# STM32MP157 register map
File version: 1.6
CPU: CM4 r0p1, little endian, no MPU, FPU, 4 interrupt priority bits
Registers are 32-bit, read-write, reset 0x0 unless marked. A register's access mark holds for its fields unless they carry their own. Offsets are from the block's base; [hi:lo] are bit positions; {n}, {i} and the like mark numbered series.

## ETZPC
Base 0x5C007000
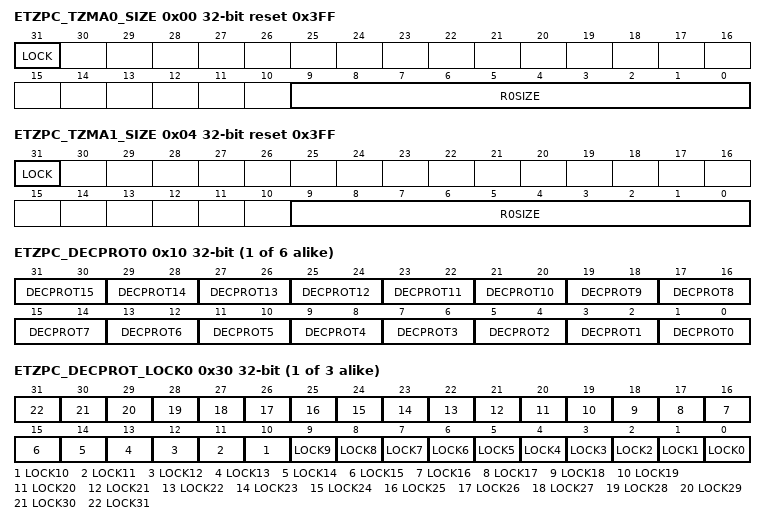
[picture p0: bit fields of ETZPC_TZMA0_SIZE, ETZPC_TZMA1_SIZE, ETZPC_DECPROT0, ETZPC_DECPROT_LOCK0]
0x00 ETZPC_TZMA0_SIZE reset 0x3FF — ETZPC ROM secure size definition
  [31] LOCK, [9:0] R0SIZE
0x04 ETZPC_TZMA1_SIZE reset 0x3FF — ETZPC RAM secure size definition
  [31] LOCK, [9:0] R0SIZE
{0x10+4i} ETZPC_DECPROT{i} (i=0..5) — Register reset values
  [2n+1:2n] DECPROT{n} (n=0..15)
{0x30+4i} ETZPC_DECPROT_LOCK{i} (i=0..2)
  [n] LOCK{n} (n=0..31)
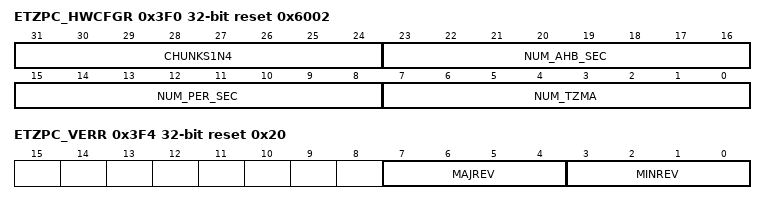
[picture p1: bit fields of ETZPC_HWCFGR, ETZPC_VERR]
0x3F0 ETZPC_HWCFGR ro reset 0x6002 — ETZPC IP HW configuration register
  [31:24] CHUNKS1N4, [23:16] NUM_AHB_SEC, [15:8] NUM_PER_SEC, [7:0] NUM_TZMA
0x3F4 ETZPC_VERR ro reset 0x20 — ETZPC IP version register
  [7:4] MAJREV, [3:0] MINREV
0x3F8 ETZPC_IDR ro reset 0x100061 — ETZPC IP version register
  [31:0] ID
0x3FC ETZPC_SIDR ro reset 0xA3C5DD01 — ETZPC IP version register
  [31:0] SID

## GICC
Base 0xA0022000
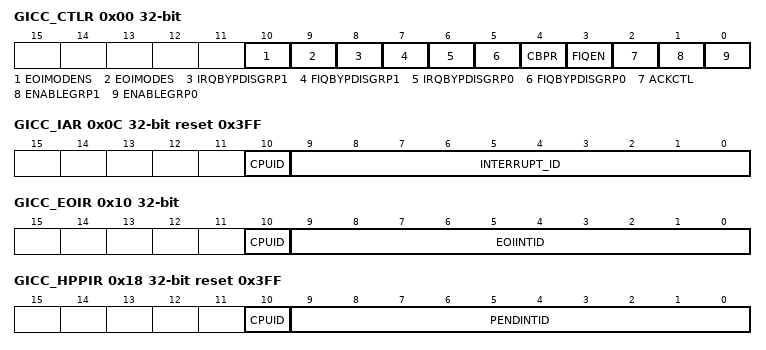
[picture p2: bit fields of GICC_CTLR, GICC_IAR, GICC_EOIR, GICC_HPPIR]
0x00 GICC_CTLR — GICC control register
  [10] EOIMODENS, [9] EOIMODES, [8] IRQBYPDISGRP1, [7] FIQBYPDISGRP1, [6] IRQBYPDISGRP0, [5] FIQBYPDISGRP0, [4] CBPR, [3] FIQEN, [2] ACKCTL, [1] ENABLEGRP1, [0] ENABLEGRP0
0x04 GICC_PMR — GICC input priority mask register
  [7:3] PRIORITY
0x08 GICC_BPR reset 0x2 — GICC binary point register
  [2:0] BINARY_POINT
0x0C GICC_IAR ro reset 0x3FF — GICC interrupt acknowledge register
  [10] CPUID, [9:0] INTERRUPT_ID
0x10 GICC_EOIR wo — GICC end of interrupt register
  [10] CPUID, [9:0] EOIINTID
0x14 GICC_RPR ro reset 0xFF — GICC running priority register
  [7:3] PRIORITY
0x18 GICC_HPPIR ro reset 0x3FF — GICC highest priority pending interrupt register
  [10] CPUID, [9:0] PENDINTID
0x1C GICC_ABPR reset 0x3 — GICC_ABPR is an alias of the non-secure GICC_BPR. When GICC_CTLR.CBPR is set to 0, a secure access to this register is equivalent to a non-secure access to GICC_BPR.
  [2:0] BINARY_POINT
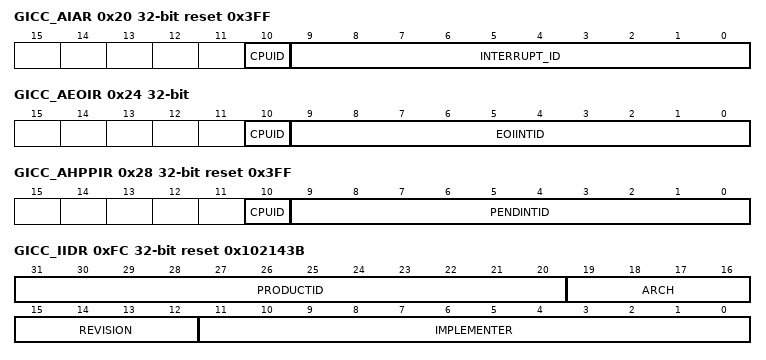
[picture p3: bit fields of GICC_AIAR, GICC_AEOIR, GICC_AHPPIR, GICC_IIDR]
0x20 GICC_AIAR ro reset 0x3FF — GICC_AIAR is an alias of the non-secure view of GICC_IAR. A secure access to this register is identical to a non-secure access to GICC_IAR.
  [10] CPUID, [9:0] INTERRUPT_ID
0x24 GICC_AEOIR wo — GICC_AEOIR is an alias of the Non-secure GICC_EOIR. A secure access to this register is similar to a non-secure access to GICC_EOIR, except that the GICC_CTLR.EOImodeS bit is used.
  [10] CPUID, [9:0] EOIINTID
0x28 GICC_AHPPIR ro reset 0x3FF — ICC_AHPPIR is an alias of the non-secure GICC_HPPIR. A secure access to this register is equivalent to a non-secure access to GICC_HPPIR.
  [10] CPUID, [9:0] PENDINTID
0xD0 GICC_APR0 — GICC active priority register
0xE0 GICC_NSAPR0 — GICC non-secure active priority register
0xFC GICC_IIDR ro reset 0x102143B — GICC interface identification register
  [31:20] PRODUCTID, [19:16] ARCH, [15:12] REVISION, [11:0] IMPLEMENTER
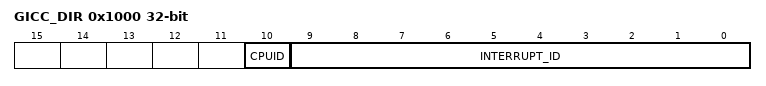
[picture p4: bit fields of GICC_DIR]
0x1000 GICC_DIR wo — GICC deactivate interrupt register
  [10] CPUID, [9:0] INTERRUPT_ID

## GICD
Base 0xA0021000
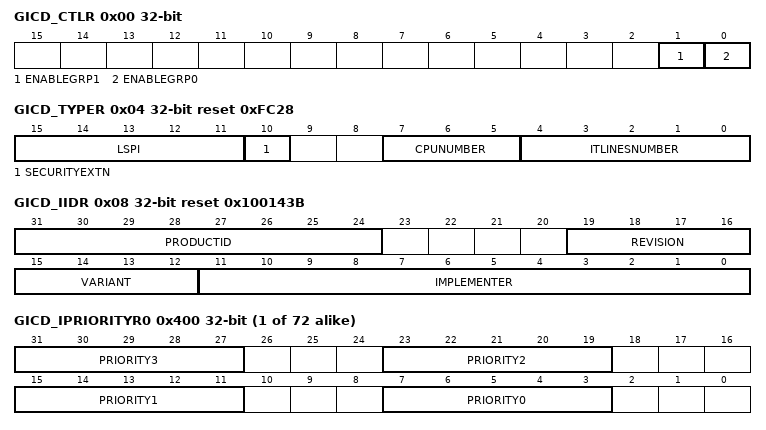
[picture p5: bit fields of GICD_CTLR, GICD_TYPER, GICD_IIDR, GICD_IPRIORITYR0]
0x00 GICD_CTLR — GICD control register
  [1] ENABLEGRP1, [0] ENABLEGRP0
0x04 GICD_TYPER ro reset 0xFC28 — GICD interrupt controller type register
  [15:11] LSPI, [10] SECURITYEXTN, [7:5] CPUNUMBER, [4:0] ITLINESNUMBER
0x08 GICD_IIDR ro reset 0x100143B — GICD implementer identification register
  [31:24] PRODUCTID, [19:16] REVISION, [15:12] VARIANT, [11:0] IMPLEMENTER
{0x80+4i} GICD_IGROUPR{i} (i=0..2) — For interrupts ID
0x8C GICD_IGROUPR3 — For interrupts ID = x*32 to ID = x*32+31
0x90 GICD_IGROUPR4 — For interrupts ID = x*32 to ID = x*32+31
{0x80+4i} GICD_IGROUPR{i} (i=5..8) — For interrupts ID
0x100 GICD_ISENABLER0 reset 0xFFFF — For interrupts ID = 0 to ID = 31
{0x100+4i} GICD_ISENABLER{i} (i=1..8) — For interrupts ID
0x180 GICD_ICENABLER0 reset 0xFFFF — For interrupts ID = 0 to ID = 31
{0x180+4i} GICD_ICENABLER{i} (i=1..8) — For interrupts ID
{0x200+4i} GICD_ISPENDR{i} (i=0..8) — For interrupts ID
{0x280+4i} GICD_ICPENDR{i} (i=0..8) — For interrupts ID
{0x300+4i} GICD_ISACTIVER{i} (i=0..8) — For interrupts ID
{0x380+4i} GICD_ICACTIVER{i} (i=0..8) — For interrupts ID
{0x400+4i} GICD_IPRIORITYR{i} (i=0..71) — GICD interrupt priority register {i}
  [8n+7:8n+3] PRIORITY{n} (n=0..3)
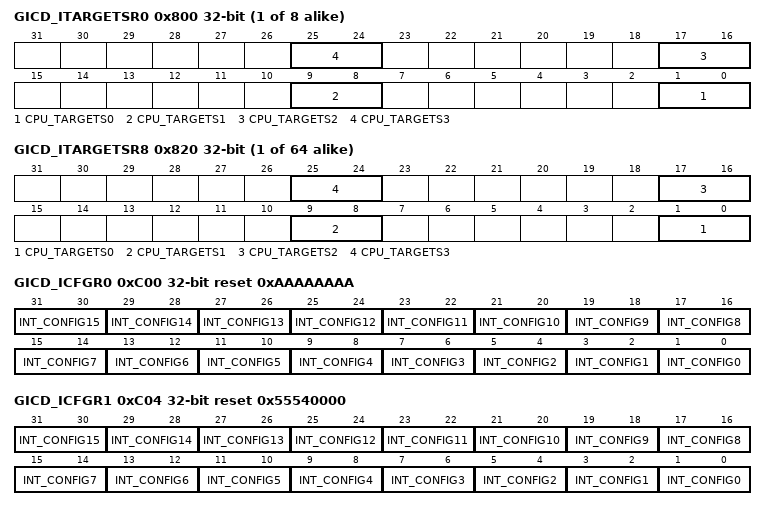
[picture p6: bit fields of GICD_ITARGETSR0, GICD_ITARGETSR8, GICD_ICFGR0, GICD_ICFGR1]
{0x800+4i} GICD_ITARGETSR{i} ro (i=0..7) — For existing SGIs and PPIs, read of CPU targets field returns the number of the processor performing the read.
  [8n+1:8n] CPU_TARGETS{n} (n=0..3)
{0x800+4i} GICD_ITARGETSR{i} (i=8..71) — GICD interrupt processor target register {i}
  [8n+1:8n] CPU_TARGETS{n} (n=0..3)
0xC00 GICD_ICFGR0 reset 0xAAAAAAAA — GICD interrupt configuration register
  [2n+1:2n] INT_CONFIG{n} (n=0..15)
0xC04 GICD_ICFGR1 reset 0x55540000 — GICD interrupt configuration register
  [2n+1:2n] INT_CONFIG{n} (n=0..15)
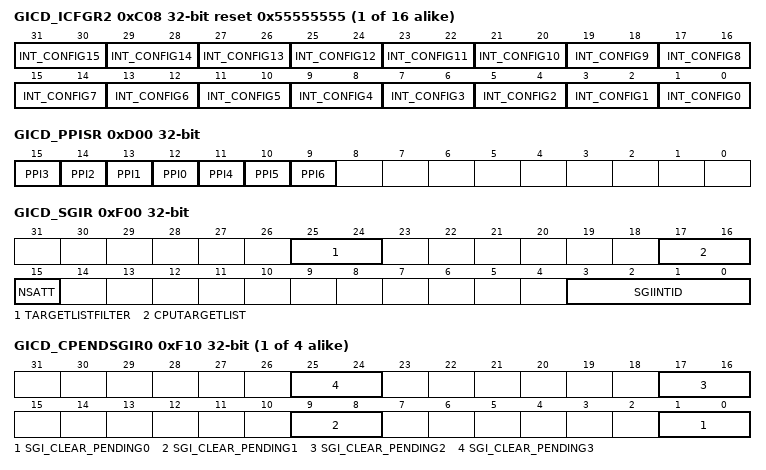
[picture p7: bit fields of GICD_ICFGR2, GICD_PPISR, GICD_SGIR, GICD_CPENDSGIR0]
{0xC00+4i} GICD_ICFGR{i} reset 0x55555555 (i=2..17) — GICD interrupt configuration register {i}
  [2n+1:2n] INT_CONFIG{n} (n=0..15)
0xD00 GICD_PPISR ro — GICD private peripheral interrupt status register
  [n+12] PPI{n} (n=0..3), [11] PPI4, [10] PPI5, [9] PPI6
0xD08 GICD_SPISR1 ro — For interrupts ID = SPI number+32, from SPI [x*32+31] to SPI [x*32]
{0xD04+4i} GICD_SPISR{i} ro (i=2..7) — For interrupts ID
0xF00 GICD_SGIR wo — GICD software generated interrupt register
  [25:24] TARGETLISTFILTER, [17:16] CPUTARGETLIST, [15] NSATT, [3:0] SGIINTID
{0xF10+4i} GICD_CPENDSGIR{i} (i=0..3) — For SGI x*4 to SGI x*4+3
  [8n+1:8n] SGI_CLEAR_PENDING{n} (n=0..3)
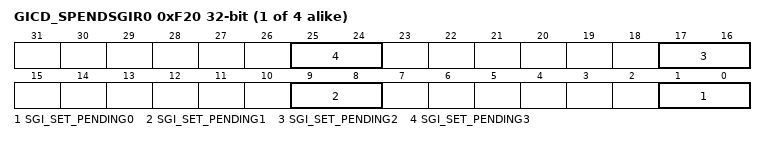
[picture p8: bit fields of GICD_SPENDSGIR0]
{0xF20+4i} GICD_SPENDSGIR{i} (i=0..3) — For SGI x*4 to SGI x*4+3
  [8n+1:8n] SGI_SET_PENDING{n} (n=0..3)
0xFD0 GICD_PIDR4 ro reset 0x4 — GICD peripheral ID4 register
{0xFC0+4i} GICD_PIDR{i} ro (i=5..7) — GICD peripheral ID5 to ID7 register {i}
0xFE0 GICD_PIDR0 ro reset 0x90 — GICD peripheral ID0 register
0xFE4 GICD_PIDR1 ro reset 0xB4 — GICD peripheral ID1 register
0xFE8 GICD_PIDR2 ro reset 0x2B — GICD peripheral ID2 register
0xFEC GICD_PIDR3 ro — GICD peripheral ID3 register
0xFF0 GICD_CIDR0 ro reset 0xD — GICD component ID0 register
0xFF4 GICD_CIDR1 ro reset 0xF0 — GICD component ID1 register
0xFF8 GICD_CIDR2 ro reset 0x5 — GICD component ID2 register
0xFFC GICD_CIDR3 ro reset 0xB1 — GICD component ID3 register
